# CY8C4xxx register map
File version: 0.1
Registers are 8-bit, read-write, no defined reset value unless marked. A register's access mark holds for its fields unless they carry their own. Offsets are from the block's base; [hi:lo] are bit positions; {n}, {i} and the like mark numbered series; 'fields as' and 'values as' point back to an identical list.

## UDB_BCTL0 — UDB Array Bank Control
Base 0x400F6000; alternate view of UDB
0x00 DRV — Master Digital Clock Drive Register
  [7:0] DRV — Master digital clock drive enable for the digital clock that matches the index.
    0=DISABLE; 1=ENABLE
0x01 MDCLK_EN — Master Digital Clock Enable Register
  [7:0] DCEN — Master digital clock enable for the digital clock that matches the index.
    0=DISABLE; 1=ENABLE
0x02 MBCLK_EN — Master Digital Clock Enable Register
  [0] BCEN — Bank Clock Enable Control
    0=DISABLE; 1=ENABLE
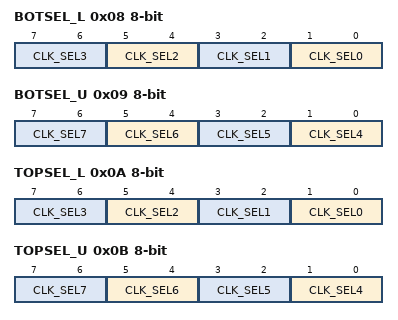
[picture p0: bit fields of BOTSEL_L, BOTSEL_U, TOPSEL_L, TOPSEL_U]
0x08 BOTSEL_L — Lower Nibble Bottom Digital Clock Select Register
  [all] fields
    0=EDGE_ENABLES; 1=PORT_INPUT; 2=DSI_OUTPUT; 3=SYNC_DSI_OUTPUT
  [2n+1:2n] CLK_SEL{n} (n=0..3) — Clock selection control for digital clock
0x09 BOTSEL_U — Upper Nibble Bottom Digital Clock Select Register
  [all] fields
    values as the fields of BOTSEL_L
  [2n-7:2n-8] CLK_SEL{n} (n=4..7) — Clock selection control for digital clock
0x0A TOPSEL_L — Lower Nibble Top Digital Clock Select Register
  fields as BOTSEL_L
0x0B TOPSEL_U — Upper Nibble Top Digital Clock Select Register
  fields as BOTSEL_U
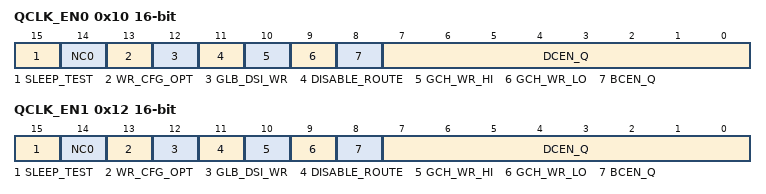
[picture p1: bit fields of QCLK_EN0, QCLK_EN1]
0x10 QCLK_EN0 16-bit — Quadrant Digital Clock Enable Registers
  [15] SLEEP_TEST — Assertion of this bit drives sleep into the s8udb array for internal s8udb test purposes. Assertion does not affect the power switches. This signal drives pulldowns on the write strobes for all configuration memory, inhibiting writes when set. Sleep or sleep_test does not inhibit writes to this bit, allowing it to be cleared once it has been set. Control is split top and bottom. BCTL0_BCLK_EN0 controls Bank 0 UDB pairs 0-3 and DSI blocks 0-3. BCTL0_BCLK_EN3 controls Bank 0 UDB pairs 4-7 and DSI blocks 4-7. The SLEEP_TEST bits in the other BCTLx_BCLK_ENy registers are not used. Sleep assertion drives bus_rdata to zero so bus read transactions will not return data during assertion of certain sleep_test bits. This is only true for assertion of sleep_test in BCTL0_BCLK_EN0 for Bank 0.
    0=DISABLE; 1=ENABLE
  [14] NC0 — Spare register bit
  [13] WR_CFG_OPT — Select 1/2 clock cycle or full clock cycle generation for bus_last_strobe used in generating write strobes for latches within the UDB. Only one BCLK_ENx register per bank has an active bit. BCTL0_BCLK_EN0 controls this bit for Bank 0. The WR_CFG_OPT bits in the other BCTLx_BCLK_ENy registers are not used.
    0=FULL_CYCLE_STB; 1=HALF_CYCLE_STB
  [12] GLB_DSI_WR — Enable global write operation for the DSI routing channels. When this bit is set, the DSI ID select decoding is bypassed and therefore multiple channels can be written to simultaneously. This is designed to support test modes. Control is split top and bottom. BCTL0_BCLK_EN0 controls DSI blocks 0-3. BCTL0_BCLK_EN3 controls DSI blocks 4-7. The GLB_DSI_WR bits in the other BCTLx_BCLK_ENy registers are not used.
    0=DISABLE; 1=ENABLE
  [11] DISABLE_ROUTE — By default, when this bit is set to '0', the quadrant routing (for 2 channels in the quadrant) are enabled when the global route enable for the bank is set. However, when this bit is set to '1', the routing in the associated quadrant is disabled and is not enabled by the global route enable bit. The routing will remain in a benign state until it is subsequently configured and then enabled by clearing this bit.
    0=DISABLE; 1=ENABLE
  [10] GCH_WR_HI — Enable global write operation for the routing channel with the higher address in the associated quadrant. When enabled, the UDB ID select decoding is bypassed and therefore multiple channels can be written to simultaneously. This is designed to support test modes.
    0=DISABLE; 1=ENABLE
  [9] GCH_WR_LO — Enable global write operation for the routing channel with the lower address in the associated quadrant. When enabled, the UDB ID select decoding is bypassed and therefore multiple channels can be written to simultaneously. This is designed to support test modes.
    0=DISABLE; 1=ENABLE
  [8] BCEN_Q — Bank Clock Enable Control
    0=DISABLE; 1=ENABLE
  [7:0] DCEN_Q — Digital clock enable for indexed digital clock for the associated quadrant.
    0=DISABLE; 1=ENABLE
0x12 QCLK_EN1 16-bit — Quadrant Digital Clock Enable Registers
  fields as QCLK_EN0
